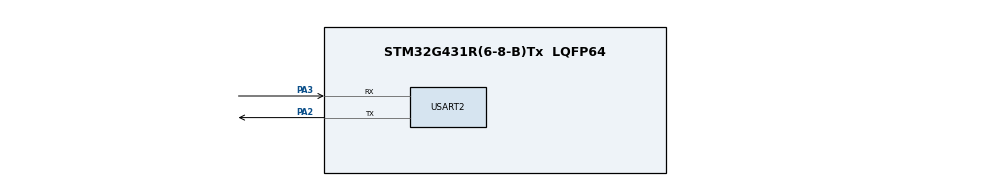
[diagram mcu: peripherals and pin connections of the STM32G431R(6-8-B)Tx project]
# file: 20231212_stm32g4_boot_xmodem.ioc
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Mcu.Family=STM32G4
Mcu.Name=STM32G431R(6-8-B)Tx
Mcu.Package=LQFP64
NVIC.PriorityGroup=NVIC_PRIORITYGROUP_4
PA2.Mode=Asynchronous
PA2.Signal=USART2_TX
PA3.Mode=Asynchronous
PA3.Signal=USART2_RX
ProjectManager.HeapSize=0x200
ProjectManager.StackSize=0x400
ProjectManager.TargetToolchain=MDK-ARM V5
RCC.ADC12Freq_Value=64000000
RCC.AHBFreq_Value=64000000
RCC.APB1Freq_Value=64000000
RCC.APB1TimFreq_Value=64000000
RCC.APB2Freq_Value=64000000
RCC.APB2TimFreq_Value=64000000
RCC.CortexFreq_Value=64000000
RCC.EXTERNAL_CLOCK_VALUE=12288000
RCC.HCLKFreq_Value=64000000
RCC.HSE_VALUE=8000000
RCC.HSI48_VALUE=48000000
RCC.HSI_VALUE=16000000
RCC.LSE_VALUE=32768
RCC.SYSCLKFreq_VALUE=64000000
RCC.SYSCLKSource=RCC_SYSCLKSOURCE_PLLCLK
RCC.USBFreq_Value=64000000
RCC.VCOOutputFreq_Value=128000000
USART2.VirtualMode-Asynchronous=VM_ASYNC
VP_SYS_VS_DBSignals.Mode=DisableDeadBatterySignals
board=custom

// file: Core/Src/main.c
/* USER CODE BEGIN Header */
/**
  ******************************************************************************
  * @file           : main.c
  * @brief          : Main program body
  ******************************************************************************
  * @attention
  *
  * Copyright (c) 2023 STMicroelectronics.
  * All rights reserved.
  *
  * This software is licensed under terms that can be found in the LICENSE file
  * in the root directory of this software component.
  * If no LICENSE file comes with this software, it is provided AS-IS.
  *
  ******************************************************************************
  */
/* USER CODE END Header */
#include "main.h"

UART_HandleTypeDef huart2;

void SystemClock_Config(void);
static void MX_GPIO_Init(void);
static void MX_USART2_UART_Init(void);

/* USER CODE BEGIN 0 */
int _write(int file, char *ptr, int len)
{
  HAL_UART_Transmit(&huart2, (uint8_t *)ptr, len, HAL_MAX_DELAY);
  return len;
}
/* USER CODE END 0 */

int main(void)
{

  /* MCU Configuration--------------------------------------------------------*/

  /* Reset of all peripherals, Initializes the Flash interface and the Systick. */
  HAL_Init();

  /* Configure the system clock */
  SystemClock_Config();

  /* Initialize all configured peripherals */
  MX_GPIO_Init();
  MX_USART2_UART_Init();
  /* USER CODE BEGIN 2 */
  uart_transmit_str((uint8_t*)"\r\n\r\n");
  uart_transmit_str((uint8_t*)"***********************************************************\r\n");
  uart_transmit_str((uint8_t*)"                  STM32G4 Bootloader\r\n");

  Main_Menu();
  /* USER CODE END 2 */

  /* Infinite loop */
  while (1)
  {

  }
}

void SystemClock_Config(void)
{
  LL_FLASH_SetLatency(LL_FLASH_LATENCY_2);
  while(LL_FLASH_GetLatency() != LL_FLASH_LATENCY_2)
  {
  }
  LL_PWR_SetRegulVoltageScaling(LL_PWR_REGU_VOLTAGE_SCALE1);
  LL_RCC_HSI_Enable();
   /* Wait till HSI is ready */
  while(LL_RCC_HSI_IsReady() != 1)
  {
  }

  LL_RCC_HSI_SetCalibTrimming(64);
  LL_RCC_PLL_ConfigDomain_SYS(LL_RCC_PLLSOURCE_HSI, LL_RCC_PLLM_DIV_1, 8, LL_RCC_PLLR_DIV_2);
  LL_RCC_PLL_EnableDomain_SYS();
  LL_RCC_PLL_Enable();
   /* Wait till PLL is ready */
  while(LL_RCC_PLL_IsReady() != 1)
  {
  }

  LL_RCC_SetSysClkSource(LL_RCC_SYS_CLKSOURCE_PLL);
   /* Wait till System clock is ready */
  while(LL_RCC_GetSysClkSource() != LL_RCC_SYS_CLKSOURCE_STATUS_PLL)
  {
  }

  /* Set AHB prescaler*/
  LL_RCC_SetAHBPrescaler(LL_RCC_SYSCLK_DIV_1);
  LL_RCC_SetAPB1Prescaler(LL_RCC_APB1_DIV_1);
  LL_RCC_SetAPB2Prescaler(LL_RCC_APB2_DIV_1);
  LL_SetSystemCoreClock(64000000);

   /* Update the time base */
  if (HAL_InitTick (TICK_INT_PRIORITY) != HAL_OK)
  {
    Error_Handler();
  }
}

static void MX_USART2_UART_Init(void)
{

  huart2.Instance = USART2;
  huart2.Init.BaudRate = 115200;
  huart2.Init.WordLength = UART_WORDLENGTH_8B;
  huart2.Init.StopBits = UART_STOPBITS_1;
  huart2.Init.Parity = UART_PARITY_NONE;
  huart2.Init.Mode = UART_MODE_TX_RX;
  huart2.Init.HwFlowCtl = UART_HWCONTROL_NONE;
  huart2.Init.OverSampling = UART_OVERSAMPLING_16;
  huart2.Init.OneBitSampling = UART_ONE_BIT_SAMPLE_DISABLE;
  huart2.Init.ClockPrescaler = UART_PRESCALER_DIV1;
  huart2.AdvancedInit.AdvFeatureInit = UART_ADVFEATURE_NO_INIT;
  if (HAL_UART_Init(&huart2) != HAL_OK)
  {
    Error_Handler();
  }
  if (HAL_UARTEx_SetTxFifoThreshold(&huart2, UART_TXFIFO_THRESHOLD_1_8) != HAL_OK)
  {
    Error_Handler();
  }
  if (HAL_UARTEx_SetRxFifoThreshold(&huart2, UART_RXFIFO_THRESHOLD_1_8) != HAL_OK)
  {
    Error_Handler();
  }
  if (HAL_UARTEx_DisableFifoMode(&huart2) != HAL_OK)
  {
    Error_Handler();
  }

}

static void MX_GPIO_Init(void)
{

  /* GPIO Ports Clock Enable */
  __HAL_RCC_GPIOA_CLK_ENABLE();

}

/* USER CODE BEGIN 4 */
void System_DeInit(void)
{
  HAL_RCC_DeInit();
}
/* USER CODE END 4 */

void Error_Handler(void)
{
  __disable_irq();
  while (1)
  {
  }
}

#ifdef  USE_FULL_ASSERT
/**
  * @brief  Reports the name of the source file and the source line number
  *         where the assert_param error has occurred.
  * @param  file: pointer to the source file name
  * @param  line: assert_param error line source number
  * @retval None
  */
void assert_failed(uint8_t *file, uint32_t line)
{
  /* USER CODE BEGIN 6 */
  /* User can add his own implementation to report the file name and line number,
     ex: uart_transmit_str((uint8_t*)"Wrong parameters value: file %s on line %d\r\n", file, line) */
  /* USER CODE END 6 */
}
#endif /* USE_FULL_ASSERT */
